# MEC1322 register map
Vendor: Microchip Technology Inc.; Series: ARMCM4F; File version: 1.0
CPU: CM4 r1p0, little endian, MPU, FPU, 3 interrupt priority bits
Registers are 32-bit, read-write, reset 0x0 unless marked. A register's access mark holds for its fields unless they carry their own. Offsets are from the block's base; [hi:lo] are bit positions; lines under a group give offsets from that group; {n}, {i} and the like mark numbered series.

## PS2 — There are four PS/2 Ports in the MEC1320 which are directly controlled by the EC. The hardware implementation eliminates the need to bit bang I/O ports to generate. PS/2 traffic, however bit banging is available via the associated GPIO pins.
Base 0x40009000
{0x0+0x40*i} CH[{i}] (i=0..3) group — Channel implemented will have these registers to determine that channel's operation.
  0x00 TX_DATA wo — Writes to this register start a transmission of the data in this register to the peripheral
  0x00 RX_DATA ro reset 0xFF — Data received from a peripheral are recorded in this register.
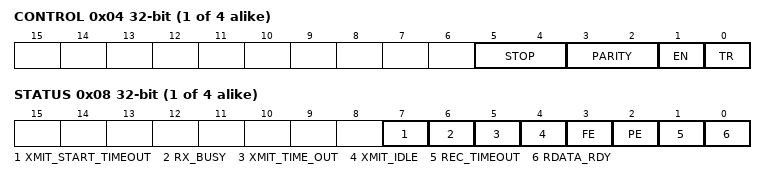
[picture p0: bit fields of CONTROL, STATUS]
  0x04 CONTROL — PS2 Control Register
    [5:4] STOP — 00b=Receiver expects an active high stop bit. 01b=Receiver expects an active low stop bit. 10b=Receiver ignores the level of the Stop bit (11th bit is not interpreted as a stop bit). 11b=Reserved.
    [3:2] PARITY — 00b=Receiver expects Odd Parity (default). 01b=Receiver expects Even Parity. 10b=Receiver ignores level of the parity bit (10th bit is not interpreted as a parity bit). 11b=Reserved
    [1] EN — PS/2 Enable. 0=The PS/2 state machine is disabled. 1=The PS/2 state machine is enabled.
    [0] TR — PS/2 Transmit/Receive. 0=The P2/2 channel is enabled to receive data. 1=The PS2 channel is enabled to transmit data.
  0x08 STATUS — PS2 Status Register
    [7] XMIT_START_TIMEOUT — Transmit Start Timeout. 0=No transmit start timeout detected. 1=A start bit was not received within 25 ms following the transmit start event. The transmit start bit time-out condition is also indicated by the XMIT_TIMEOUT bit.
    [6] RX_BUSY — Receive Channel Busy. 0=The channel is actively receiving PS/2 data. 1=The channel is idle
    [5] XMIT_TIME_OUT — Transmitter Time-out. When the XMIT_TIMEOUT bit is set, the PS2_T/R bit is held clear, the PS/2 channel's CLK line is pulled low for a minimum of 300us until the PS/2 Status register is read.
    [4] XMIT_IDLE — Transmitter Idle. 0=The channel is actively transmitting PS/2 data. 1=The channel is not transmitting. A low to high transition on this bit generates a PS2 Activity interrupt.
    [3] FE — Framing Error
    [2] PE — Parity Error
    [1] REC_TIMEOUT — Receive Timeout. The REC_TIMEOUT bit is cleared when the Status Register is read. A low to high transition on this bit generates a PS2 Activity interrupt. (R/WC)
    [0] RDATA_RDY ro — Receive Data Ready. Reading the Receive Register clears this bit. A low to high transition on this bit generates a PS2 Activity interrupt.

## KMS — The Keyboard Scan Interface block provides a register interface to the EC to directly scan an external keyboard matrix of size up to 18x8.
Base 0x40009C00
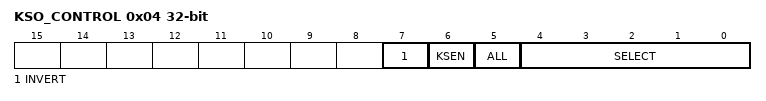
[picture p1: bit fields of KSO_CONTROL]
0x04 KSO_CONTROL — KSO Select and control
  [7] INVERT — 0= KSO[x] driven low when selected, 1= KSO[x] driven high when selected.
  [6] KSEN — 0= Keyboard scan enabled, 1= Keyboard scan disabled. All KSO output buffers disabled.
  [5] ALL — 0=When key scan is enabled, KSO output controlled by the KSO_SELECT field. 1=KSO[x] driven high when selected.
  [4:0] SELECT — This field selects a KSO line (00000b = KSO[0] etc.) for output according to the value off KSO_INVERT in this register.
0x08 KSI ro — [7:0] This field returns the current state of the KSI pins.
0x0C KSI_STATUS — [7:0] Each bit in this field is set on the falling edge of the corresponding KSI input pin. A KSI interrupt is generated when its corresponding status bit and interrupt enable bit are both set. KSI interrupts are logically ORed together to produce KSC_INT and KSC_INT_WAKE. Writing a '1' to a bit will clear it. Writing a '0' to a bit has no effect.
0x10 KSI_INT_EN — [7:0] Each bit in KSI_INT_EN enables interrupt generation due to highto-low transition on a KSI input. An interrupt is generated when the corresponding bits in KSI_STATUS and KSI_INT_EN are both set.
0x14 EXTENDED_CONTROL — [0:0] PREDRIVE_ENABLE enables the PREDRIVE mode to actively drive the KSO pins high for approximately 100ns before switching to open-drain operation. 0=Disable predrive on KSO pins. 1=Enable predrive on KSO pins.
